# SF32LB57x register map
File version: 1.0
CPU: CM33 r0p1, little endian, MPU, FPU, 3 interrupt priority bits
Registers are 32-bit, read-write, reset 0x0 unless marked. A register's access mark holds for its fields unless they carry their own. Offsets are from the block's base; [hi:lo] are bit positions; {n}, {i} and the like mark numbered series; 'fields as' and 'values as' point back to an identical list.

## EPIC
Base 0x50007000
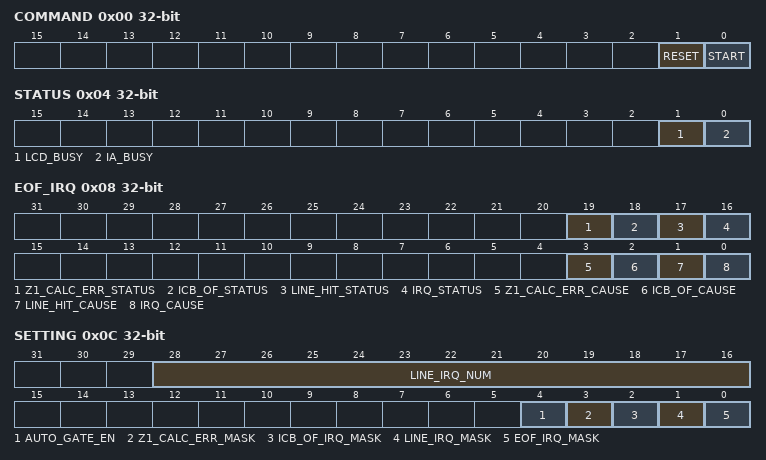
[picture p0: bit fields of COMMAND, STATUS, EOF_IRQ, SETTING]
0x00 COMMAND
  [1] RESET — 1: reset the whole graphics 0: release the reset
  [0] START — write 1 to trigger the lcd interface block
0x04 STATUS
  [1] LCD_BUSY — LCD controll busy flag
  [0] IA_BUSY — Graphics accelerator busy flag
0x08 EOF_IRQ
  [19] Z1_CALC_ERR_STATUS — raw status of z1 calculation error interrupt
  [18] ICB_OF_STATUS — raw status of decomp icb overflow interrupt
  [17] LINE_HIT_STATUS — raw status of line hit interrupt
  [16] IRQ_STATUS — raw status of end of frame interrupt
  [3] Z1_CALC_ERR_CAUSE — z1 calculation error interrupt, can be masked by Z1_CALC_ERR_MASK
  [2] ICB_OF_CAUSE — decomp icb overflow interrupt, can be masked by ICB_OF_IRQ_MASK
  [1] LINE_HIT_CAUSE — line hit interrupt, can be masked by LINE_IRQ_MASK
  [0] IRQ_CAUSE — end of frame interrupt, can be masked by EOF_IRQ_MASK
0x0C SETTING
  [28:16] LINE_IRQ_NUM — canvas line hit interrupt line number
  [4] AUTO_GATE_EN — auto clock gating enable
  [3] Z1_CALC_ERR_MASK — z1 calculation error interrupt mask, 0: mask the interrupt
  [2] ICB_OF_IRQ_MASK — icb overflow interrupt mask, 0: mask the interrupt
  [1] LINE_IRQ_MASK — canvas line hit interrupt mask, 0: mask the interrupt
  [0] EOF_IRQ_MASK — end of frame interrupt mask, 0: mask the interrupt
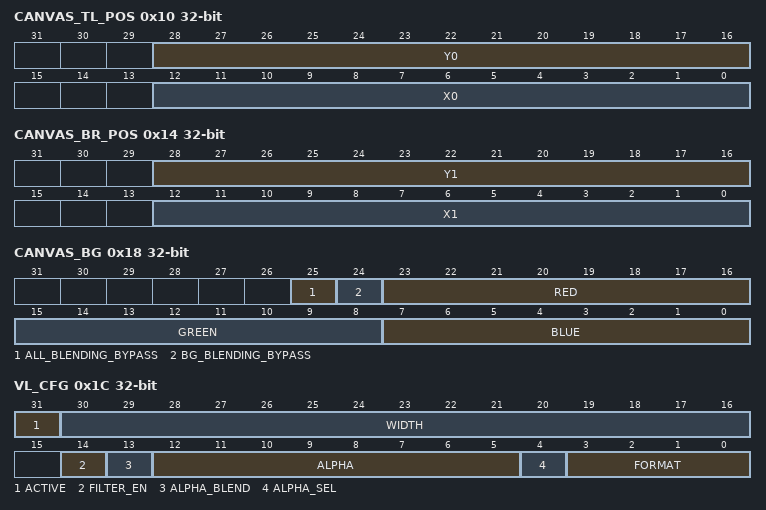
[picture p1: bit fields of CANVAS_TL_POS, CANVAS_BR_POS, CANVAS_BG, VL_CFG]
0x10 CANVAS_TL_POS — Top-Left pixel coordinate
  [28:16] Y0, [12:0] X0
0x14 CANVAS_BR_POS — Bottom-Right pixel coordinate
  [28:16] Y1, [12:0] X1
0x18 CANVAS_BG — Background color
  [25] ALL_BLENDING_BYPASS — if this bit is set, epic is in pure dma mode. No blending operation.
  [24] BG_BLENDING_BYPASS — if this bit is set, the layer is not blending with background. The alpha value will be reserved to output.
  [23:16] RED — Red color
  [15:8] GREEN — green color
  [7:0] BLUE — blue color
0x1C VL_CFG
  [31] ACTIVE — layer active flag
  [30:16] WIDTH — source image width(including padding), unit is bytes
  [14] FILTER_EN — layer color filter enable
  [13] ALPHA_BLEND — set 1 to enable alpha blending mode. Use layer alpha as blending factor for image with Alpha. Alpha_out = Layer_alpha * Image_alpha
  [12:5] ALPHA — layer alpha value
  [4] ALPHA_SEL — alpha selection 1'b0: select alpha according to image format 1'b1: select layer alpha
  [3:0] FORMAT — video layer input format 4'h0: RGB565 4'h1: RGB888 4'h2: ARGB8888 4'h3: ARGB8565 4'h4: A8 4'h5: A4 4'h6: L8 4'h7: A2 4'h8: L4 other: reserved
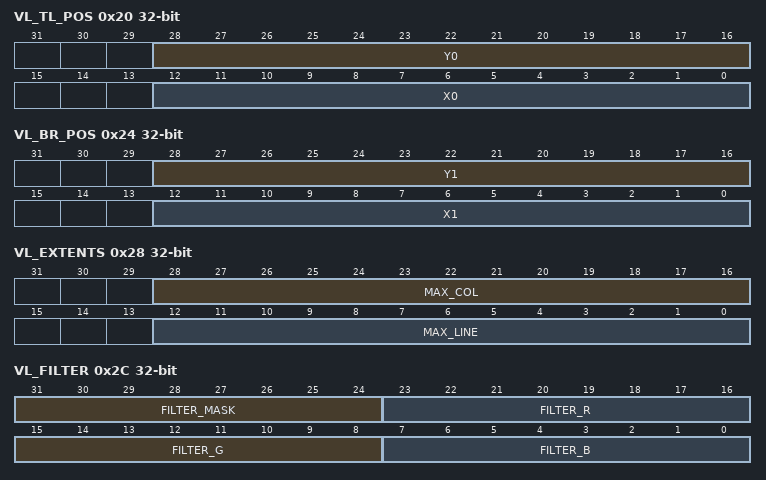
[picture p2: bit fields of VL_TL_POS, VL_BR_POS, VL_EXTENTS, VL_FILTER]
0x20 VL_TL_POS
  [28:16] Y0 — Coordingate Y-value
  [12:0] X0 — Coordinate X-value
0x24 VL_BR_POS
  [28:16] Y1 — Coordingate Y-value
  [12:0] X1 — Coordinate X-value
0x28 VL_EXTENTS
  [28:16] MAX_COL — max column number of source image(not including padding)
  [12:0] MAX_LINE — max line number of source image(not including padding)
0x2C VL_FILTER
  [31:24] FILTER_MASK — layer color filter mask
  [23:16] FILTER_R — filter r color
  [15:8] FILTER_G — filter g color
  [7:0] FILTER_B — filter b color
0x30 VL_SRC
  [31:0] ADDR — source image RGB data address[31:0]. For RGB565 format, address should be aligned to halfword. For ARGB8888 format, address should be aligned to word.
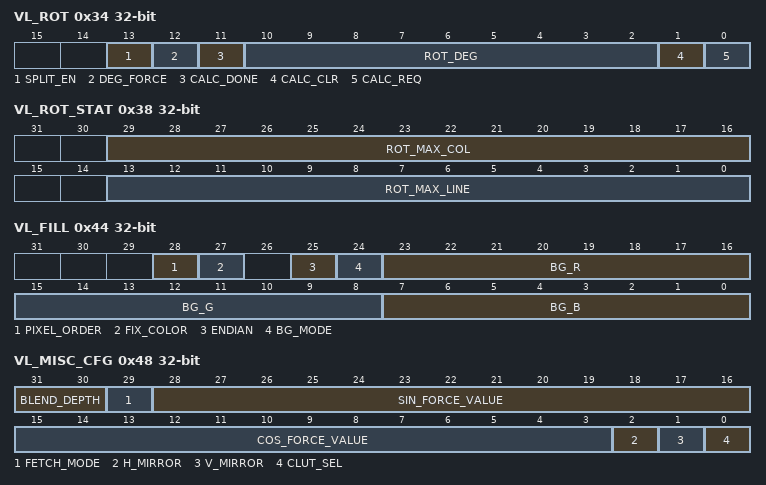
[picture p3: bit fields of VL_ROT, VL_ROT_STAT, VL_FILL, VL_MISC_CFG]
0x34 VL_ROT
  [13] SPLIT_EN — split read access of rotation
  [12] DEG_FORCE — force epic use external sin and cos value, quadrant is still calculated from ROT_DEG.
  [11] CALC_DONE — calculation done indicator
  [10:2] ROT_DEG — rotation degree, rotation is clockwise.
  [1] CALC_CLR — rot_max_col and rot_max_line calculation clear request. Write 1 to clear the result.
  [0] CALC_REQ — rot_max_col and rot_max_line calculation request. Write 1 to trigger the calculation.
0x38 VL_ROT_STAT
  [29:16] ROT_MAX_COL — max column of rotated image
  [13:0] ROT_MAX_LINE — max line of rotated image
0x3C VL_SCALE_RATIO_H
  [28:0] XPITCH — x-axis rescaling ration, 13.16 fixed point number, XPITCH lt MAX_COL/(X1-X0)
0x40 VL_SCALE_RATIO_V
  [28:0] YPITCH — y-axis rescaling ratio, 13.16 fixed point number, YPITCH lt MAX_LINE/(Y1-Y0)
0x44 VL_FILL
  [28] PIXEL_ORDER — A4, A2, L4 color format pixel order 0: ByteA4 = {P1, P0}, ByteA2 = (P3, P2, P1, P0), ByteL4 = {P1, P0} 1: ByteA4 = {P0, P1}, ByteA2 = (P0, P1, P2, P3), ByteL4 = {P0, P1}
  [27] FIX_COLOR — set this bit to 1, this layer output will be fixed to Alpha, BG_R, BG_G and BG_B
  [25] ENDIAN — input 565 data format endian 0: {R[4:0], G[5:3], G[2:0], B[4:0]} 1: {G[2:0], B[4:0], R[4:0], G[5:3]}
  [24] BG_MODE — Not used.
  [23:16] BG_R — background r color
  [15:8] BG_G — background g color
  [7:0] BG_B — background b color
0x48 VL_MISC_CFG
  [31:30] BLEND_DEPTH — video layer blending depth
  [29] FETCH_MODE — 1: use undefined length AHB transaction 0: use fixed length AHB transaction
  [28:16] SIN_FORCE_VALUE — external absolute value of sin. U1.12 format.
  [15:3] COS_FORCE_VALUE — external absolute value of cos. U1.12 format.
  [2] H_MIRROR — horizontal mirror enable
  [1] V_MIRROR — vertical mirror enable
  [0] CLUT_SEL — VL CLUT select: 1'h1: select pallette1 1'h0: select pallette0
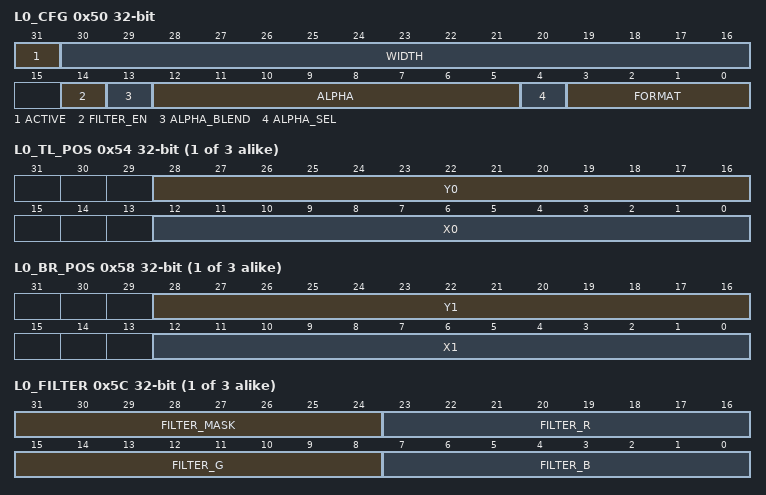
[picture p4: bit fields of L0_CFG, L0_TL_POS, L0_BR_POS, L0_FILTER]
0x50 L0_CFG
  [31] ACTIVE — layer active flag
  [30:16] WIDTH — source image width(including padding), unit is bytes
  [14] FILTER_EN — layer color filter enable
  [13] ALPHA_BLEND — set 1 to enable alpha blending mode. Use layer alpha as blending factor for image with Alpha. Alpha_out = Layer_alpha * Image_alpha
  [12:5] ALPHA — layer alpha value
  [4] ALPHA_SEL — alpha selection 1'b0: select alpha according to image format 1'b1: select layer alpha
  [3:0] FORMAT — layer input format 4'h0: RGB565 4'h1: RGB888 4'h2: ARGB8888 4'h3: ARGB8565 4'h4: A8 4'h5: A4 4'h6: L8 4'h7: A2 4'h8: L4 other: reserved
{0x54+0x20*i} L{i}_TL_POS (i=0..2)
  [28:16] Y0 — Coordingate Y-value
  [12:0] X0 — Coordinate X-value
{0x58+0x20*i} L{i}_BR_POS (i=0..2)
  [28:16] Y1 — Coordingate Y-value
  [12:0] X1 — Coordinate X-value
{0x5C+0x20*i} L{i}_FILTER (i=0..2)
  fields as VL_FILTER
{0x60+0x20*i} L{i}_SRC (i=0..2)
  fields as VL_SRC
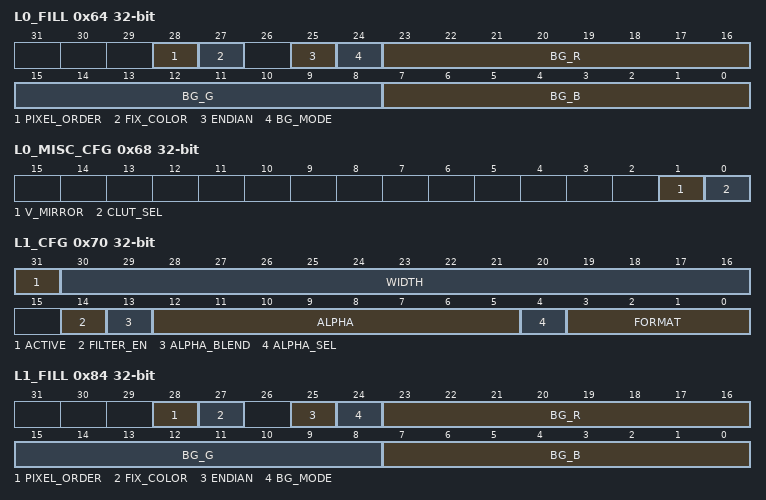
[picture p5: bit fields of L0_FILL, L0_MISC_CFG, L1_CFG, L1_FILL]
0x64 L0_FILL
  fields as VL_FILL
0x68 L0_MISC_CFG
  [1] V_MIRROR — vertical mirror enable
  [0] CLUT_SEL — L0 CLUT select: 1'h1: select pallette1 1'h0: select pallette0
0x70 L1_CFG
  fields as L0_CFG
0x84 L1_FILL
  [28] PIXEL_ORDER — A4, A2, L4 color format pixel order 0: ByteA4 = {P1, P0}, ByteA2 = (P3, P2, P1, P0), ByteL4 = {P1, P0} 1: ByteA4 = {P0, P1}, ByteA2 = (P0, P1, P2, P3), ByteL4 = {P0, P1}
  [27] FIX_COLOR — set this bit to 1, this layer output will be fixed to Alpha, BG_R, BG_G and BG_B
  [25] ENDIAN — input 565 data format endian 0: {R[4:0], G[5:3], G[2:0], B[4:0]} 1: {G[2:0], R[4:0], B[4:0], G[5:3]}
  [24] BG_MODE — Not used.
  [23:16] BG_R — background r color
  [15:8] BG_G — background g color
  [7:0] BG_B — background b color
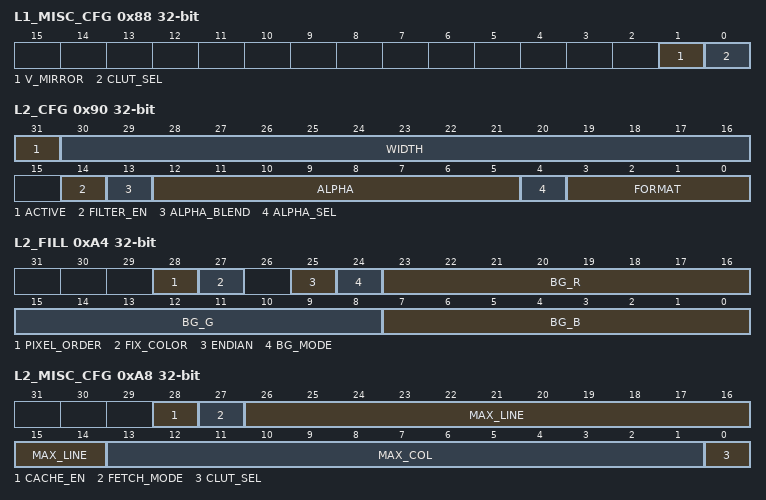
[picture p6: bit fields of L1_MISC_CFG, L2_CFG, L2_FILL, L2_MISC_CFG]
0x88 L1_MISC_CFG
  [1] V_MIRROR — vertical mirror enable
  [0] CLUT_SEL — L1 CLUT select: 1'h1: select pallette1 1'h0: select pallette0
0x90 L2_CFG
  [31] ACTIVE — layer active flag
  [30:16] WIDTH — source image width(including padding), unit is bytes
  [14] FILTER_EN — layer color filter enable
  [13] ALPHA_BLEND — set 1 to enable alpha blending mode. Use layer alpha as blending factor for image with Alpha. Alpha_out = Layer_alpha * Image_alpha
  [12:5] ALPHA — layer alpha value
  [4] ALPHA_SEL — alpha selection 1'b0: select alpha according to image format 1'b1: select layer alpha
  [3:0] FORMAT — layer input format 4'h0: RGB565 4'h1: RGB888 4'h2: ARGB8888 4'h3: ARGB8565 Other: reserved
0xA4 L2_FILL
  [28] PIXEL_ORDER — Not used.
  [27] FIX_COLOR — set this bit to 1, this layer output will be fixed to Alpha, BG_R, BG_G and BG_B
  [25] ENDIAN — input 565 data format endian 0: {R[4:0], G[5:3], G[2:0], B[4:0]} 1: {G[2:0], B[4:0], R[4:0], G[5:3]}
  [24] BG_MODE — Not used.
  [23:16] BG_R — background r color
  [15:8] BG_G — background g color
  [7:0] BG_B — background b color
0xA8 L2_MISC_CFG
  [28] CACHE_EN — 1: enable L2 data fetch cache
  [27] FETCH_MODE — 1: use undefined length AHB transaction 0: use fixed length AHB transaction
  [26:14] MAX_LINE — max line of image
  [13:1] MAX_COL — max column of image
  [0] CLUT_SEL — L1 CLUT select: 1'h1: select pallette1 1'h0: select pallette0
0xAC L2_MAT_A0
  [31:0] VAL — s12.20
0xB0 L2_MAT_A1
  [31:0] VAL — s12.20
0xB4 L2_MAT_A2
  [31:0] VAL — s16.16
0xB8 L2_MAT_B0
  [31:0] VAL — s12.20
0xBC L2_MAT_B1
  [31:0] VAL — s12.20
0xC0 L2_MAT_B2
  [31:0] VAL — s16.16
0xC4 L2_MAT_C0
  [31:0] VAL — s12.20
0xC8 L2_MAT_C1
  [31:0] VAL — s12.20
0xCC L2_MAT_C2
  [31:0] VAL — s16.16
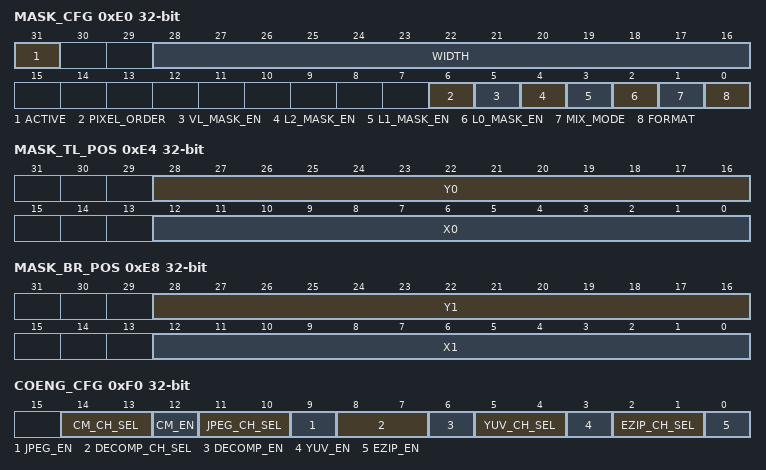
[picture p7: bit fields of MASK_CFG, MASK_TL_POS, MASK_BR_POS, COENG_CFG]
0xE0 MASK_CFG
  [31] ACTIVE — layer active flag
  [28:16] WIDTH — source image width(including padding), unit is bytes
  [6] PIXEL_ORDER — A4 color format pixel order 0: ByteA4 = {P1, P0} 1: ByteA4 = {P0, P1}
  [5] VL_MASK_EN — video layer mask enable
  [4] L2_MASK_EN — layer2 mask enable
  [3] L1_MASK_EN — layer1 mask enable
  [2] L0_MASK_EN — layer0 mask enable
  [1] MIX_MODE — mask mix mode 1'h0: mult mode 1'h1: overwrite mode
  [0] FORMAT — mask input format 1'h0: A8 1'h1: A4
0xE4 MASK_TL_POS
  [28:16] Y0 — Coordingate Y-value
  [12:0] X0 — Coordinate X-value
0xE8 MASK_BR_POS
  [28:16] Y1 — Coordingate Y-value
  [12:0] X1 — Coordinate X-value
0xEC MASK_SRC
  [31:0] ADDR — mask data address[31:0]. This is byte address, even for A4, this address is byte aligned.
0xF0 COENG_CFG
  [14:13] CM_CH_SEL — color matrix engine channel select 2'h0: VL 2'h1: OL0 2'h2: OL1 2'h3: OL2
  [12] CM_EN — color matrix enable
  [11:10] JPEG_CH_SEL — jpeg engine channel select 2'h0: VL 2'h1: OL0 2'h2: OL1 2'h3: reserved
  [9] JPEG_EN — jpeg enable
  [8:7] DECOMP_CH_SEL — decompression channel select 2'h0: VL 2'h1: OL0 2'h2: OL1 2'h3: reserved
  [6] DECOMP_EN — decompression enable
  [5:4] YUV_CH_SEL — yuv engine channel select 2'h0: VL 2'h1: OL0 2'h2: OL1 2'h3: reserved
  [3] YUV_EN — yuv enable
  [2:1] EZIP_CH_SEL — ezip channel select 2'h0: VL 2'h1: OL0 2'h2: OL1 2'h3: reserved
  [0] EZIP_EN — ezip enable
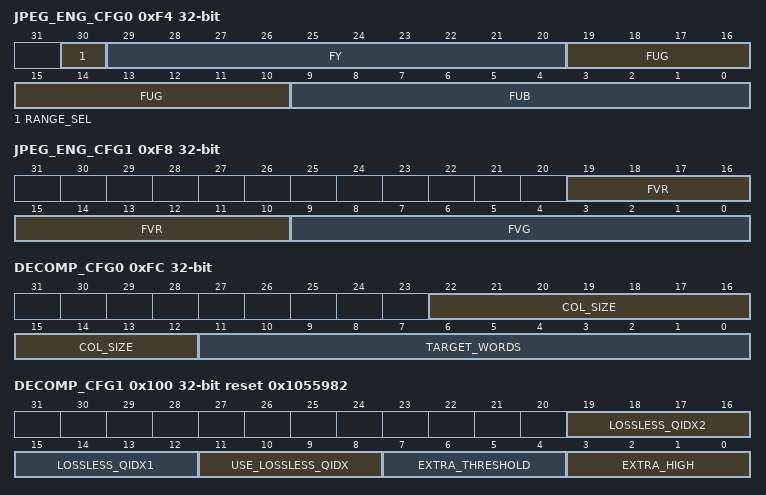
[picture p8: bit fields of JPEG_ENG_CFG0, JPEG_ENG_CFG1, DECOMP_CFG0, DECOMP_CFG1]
0xF4 JPEG_ENG_CFG0
  [30] RANGE_SEL — yuv input range 1'h0: tv range 1'h1: pc range
  [29:20] FY — YUV Fy coef
  [19:10] FUG — YUV Fug coef
  [9:0] FUB — YUV Fub coef
0xF8 JPEG_ENG_CFG1
  [19:10] FVR — YUV Fvr coef
  [9:0] FVG — YUV Fvg coef
0xFC DECOMP_CFG0
  [22:12] COL_SIZE — number of colums in a line of original image, max column size is 1024
  [11:0] TARGET_WORDS — size of a single channel data before decompression. Unit is half word. Each line has 3 channels. So for each line, the compressed data size is target_words * 3 * 2 bytes.
0x100 DECOMP_CFG1 reset 0x1055982
  [19:16] LOSSLESS_QIDX2 — condition to decrease qidx
  [15:12] LOSSLESS_QIDX1 — up level for adjusted qidx value for low quality block
  [11:8] USE_LOSSLESS_QIDX — condition to increase qidx
  [7:4] EXTRA_THRESHOLD — the threshold to distinguish high/low quality block
  [3:0] EXTRA_HIGH — extra bit for high quality bit
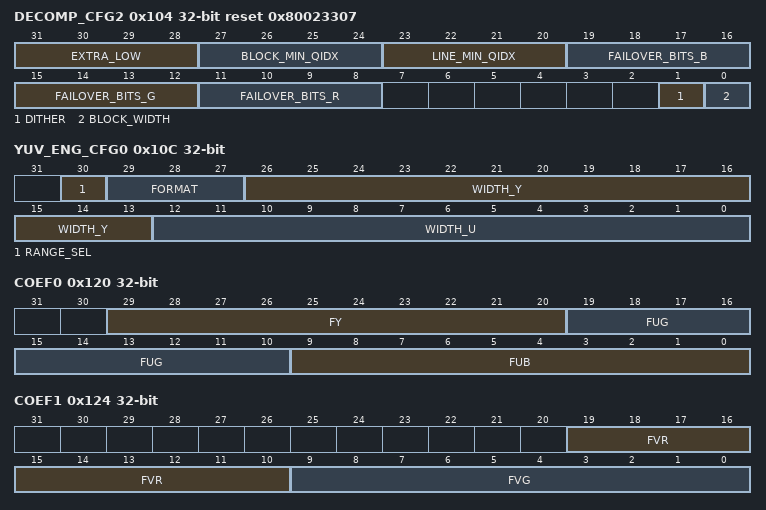
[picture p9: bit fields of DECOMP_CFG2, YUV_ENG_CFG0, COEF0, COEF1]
0x104 DECOMP_CFG2 reset 0x80023307
  [31:28] EXTRA_LOW — extra bit for low quality block
  [27:24] BLOCK_MIN_QIDX — minimum qidx for block mode
  [23:20] LINE_MIN_QIDX — minimum qidx for line mode
  [19:16] FAILOVER_BITS_B — failover compression mode target bits(Blue)
  [15:12] FAILOVER_BITS_G — failover compression mode target bits(Green)
  [11:8] FAILOVER_BITS_R — failover compression mode target bits(Red)
  [1] DITHER — dithering function 0: off 1: on
  [0] BLOCK_WIDTH — block_size in pixel unit. 0: 16 pixels 1: 32 pixels Small block size will cause more blocks and more bits to store block information.
0x108 DECOMP_STAT
  [6:0] BUF_MAX_DEPTH — buf max usage
0x10C YUV_ENG_CFG0
  [30] RANGE_SEL — yuv input range 1'h0: tv range 1'h1: pc range
  [29:27] FORMAT — yuv format
  [26:13] WIDTH_Y — yuv y vector line width, unit is bytes
  [12:0] WIDTH_U — yuv u vector line width, unit is bytes
0x110 YUV_ENG_CFG1
  [12:0] WIDTH_V — yuv v vector line width, unit is bytes
0x114 Y_SRC
  [31:0] ADDR — y vector address
0x118 U_SRC
  [31:0] ADDR — u vector address
0x11C V_SRC
  [31:0] ADDR — v vector address
0x120 COEF0
  [29:20] FY — YUV Fy coef
  [19:10] FUG — YUV Fug coef
  [9:0] FUB — YUV Fub coef
0x124 COEF1
  [19:10] FVR — YUV Fvr coef
  [9:0] FVG — YUV Fvg coef
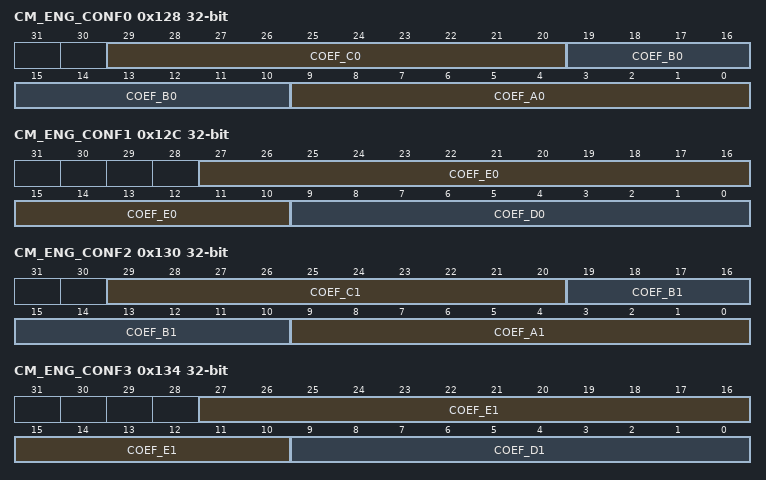
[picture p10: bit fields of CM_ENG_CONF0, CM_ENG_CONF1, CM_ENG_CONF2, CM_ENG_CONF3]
0x128 CM_ENG_CONF0
  [29:20] COEF_C0 — c0, s2.8 format
  [19:10] COEF_B0 — b0, s2.8 format
  [9:0] COEF_A0 — a0, s2.8 format
0x12C CM_ENG_CONF1
  [27:10] COEF_E0 — e0, s10.8 format
  [9:0] COEF_D0 — d0, s2.8 format
0x130 CM_ENG_CONF2
  [29:20] COEF_C1 — c1, s2.8 format
  [19:10] COEF_B1 — b1, s2.8 format
  [9:0] COEF_A1 — a1, s2.8 format
0x134 CM_ENG_CONF3
  [27:10] COEF_E1 — e1, s10.8 format
  [9:0] COEF_D1 — d1, s2.8 format
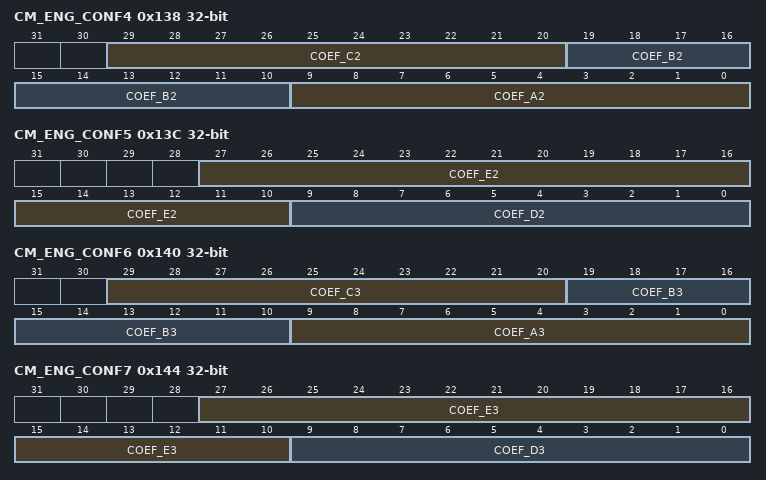
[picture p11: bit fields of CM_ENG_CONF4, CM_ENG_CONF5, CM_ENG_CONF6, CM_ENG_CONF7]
0x138 CM_ENG_CONF4
  [29:20] COEF_C2 — c2, s2.8 format
  [19:10] COEF_B2 — b2, s2.8 format
  [9:0] COEF_A2 — a2, s2.8 format
0x13C CM_ENG_CONF5
  [27:10] COEF_E2 — e2, s10.8 format
  [9:0] COEF_D2 — d2, s2.8 format
0x140 CM_ENG_CONF6
  [29:20] COEF_C3 — c3, s2.8 format
  [19:10] COEF_B3 — b3, s2.8 format
  [9:0] COEF_A3 — a3, s2.8 format
0x144 CM_ENG_CONF7
  [27:10] COEF_E3 — e3, s10.8 format
  [9:0] COEF_D3 — d3, s2.8 format
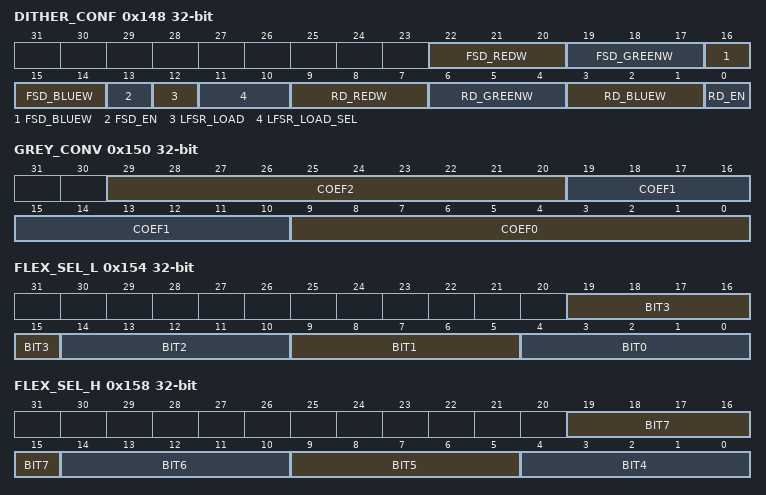
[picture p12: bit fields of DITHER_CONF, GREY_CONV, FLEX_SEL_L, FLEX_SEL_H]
0x148 DITHER_CONF
  [22:20] FSD_REDW — red regular dither width, range from 0 - 4
  [19:17] FSD_GREENW — green regular dither width, range from 0 - 4
  [16:14] FSD_BLUEW — blue regular dither width, range from 0 - 4
  [13] FSD_EN — regular dither enable
  [12] LFSR_LOAD — load random dither lfsr init value
  [11:10] LFSR_LOAD_SEL — select random dither lfsr 0: none 1: red 2: green 3: blue
  [9:7] RD_REDW — red random dither width
  [6:4] RD_GREENW — green random dither width
  [3:1] RD_BLUEW — blue random dither width
  [0] RD_EN — random dither enable
0x14C DITHER_LFSR
  [31:0] INIT_VAL — random dither lfsr init load value
0x150 GREY_CONV
  [29:20] COEF2
  [19:10] COEF1
  [9:0] COEF0 — grey = (coef0 * r + coef1 * g + coef2 * b) >> 10
0x154 FLEX_SEL_L
  [19:15] BIT3
  [14:10] BIT2
  [9:5] BIT1
  [4:0] BIT0 — bit select index from internal ARGB8888 format data
0x158 FLEX_SEL_H
  [19:15] BIT7
  [14:10] BIT6
  [9:5] BIT5
  [4:0] BIT4 — bit select index from internal ARGB8888 format data
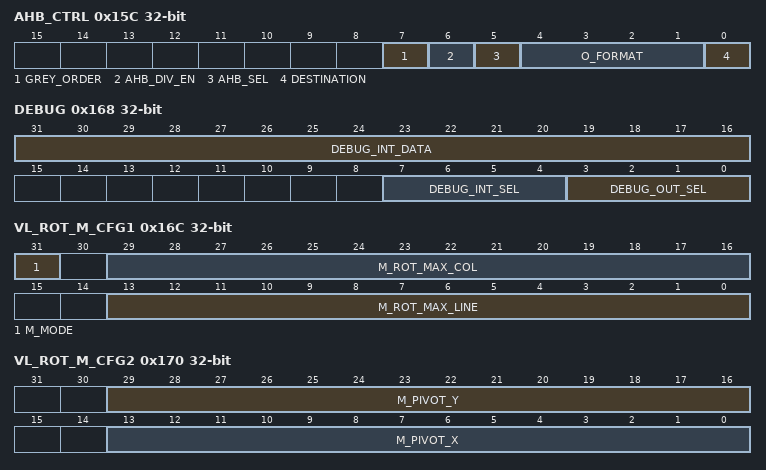
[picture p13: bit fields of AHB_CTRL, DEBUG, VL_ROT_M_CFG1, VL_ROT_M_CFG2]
0x15C AHB_CTRL
  [7] GREY_ORDER — G4/G2 format bit order 1'h0: byteG4 = {p1, p0}, byteG2 = {p3,p2,p1,p0} 1'h1: byteG4 = {p0, p1}, byteG2 = {p0,p1,p2,p3}
  [6] AHB_DIV_EN — set 1 to divide AHB undefined length burst to fix length burst
  [5] AHB_SEL — select ahb write interface: 1'b0: select AHB_A 1'b1: select AHB_B
  [4:1] O_FORMAT — AHB output format: 4'h0: RGB565 4'h1: RGB888 4'h2: ARGB8888 4'h3: ARGB8565 4'h4: A8 4'h5: G8(8 bit for 1 pixel) 4'h6: G4(4 bit for 1 pixel) 4'h7: G2(2bit for 1 pixel) 4'h8: F8(Flexible 8bit format) 4'h9: F4(Flexible 4bit format) 4'ha: F2(Flexible 2bit format) other: reserved
  [0] DESTINATION — The Data can be sent to two destinations: 2'b0: AHB RAM 2'b1: AHB LCD
0x160 AHB_MEM
  [31:0] ADDR — AHB RAM/AHB LCD target address
0x164 AHB_STRIDE
  [15:0] OFFSET
0x168 DEBUG
  [31:16] DEBUG_INT_DATA, [7:4] DEBUG_INT_SEL, [3:0] DEBUG_OUT_SEL
0x16C VL_ROT_M_CFG1
  [31] M_MODE — rotation mode setting 1'b0: auto mode 1'b1: manual mode
  [29:16] M_ROT_MAX_COL — manual mode rotation max column, unsigned value
  [13:0] M_ROT_MAX_LINE — manual mode rotation max line, unsigned value
0x170 VL_ROT_M_CFG2
  [29:16] M_PIVOT_Y — manual mode pivot y, signed value, -8191~8191, -8192 is not supported
  [13:0] M_PIVOT_X — manual mode pivot x, signed value, -8191~8191, -8192 is not supported
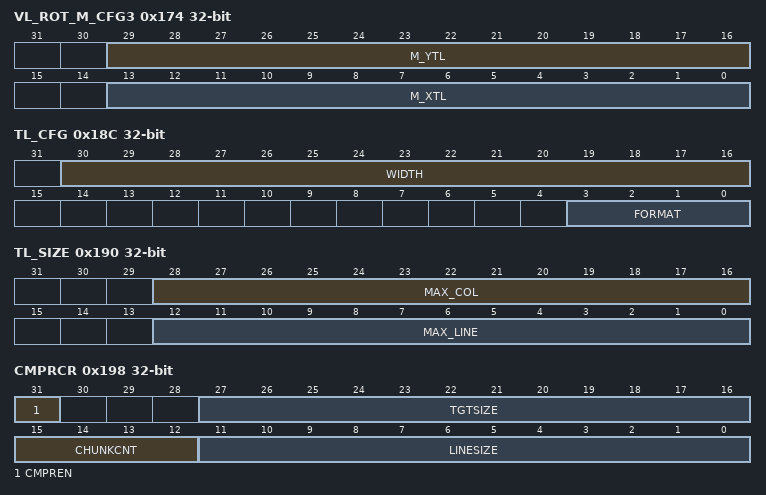
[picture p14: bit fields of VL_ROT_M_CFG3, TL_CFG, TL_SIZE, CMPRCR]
0x174 VL_ROT_M_CFG3
  [29:16] M_YTL — manual mode top left y cordinate, signed value, -8191~8191, -8192 is not supported
  [13:0] M_XTL — manual mode top left x cordinate, signed value, -8191~8191, -8192 is not supported
0x178 VL_SCALE_INIT_CFG1
  [28:0] X_VAL — x-axis scale initial value, 13.16 format
0x17C VL_SCALE_INIT_CFG2
  [28:0] Y_VAL — y-axis scale initial value, 13.16 format
0x180 AHBA_CNT
  [31:0] VAL — epic ahb_a bus busy cycle counter
0x184 AHBB_CNT
  [31:0] VAL — epic ahb_b bus busy cycle counter
0x188 PERF_CNT
  [31:0] VAL — epic performance counter
0x18C TL_CFG
  [30:16] WIDTH — source image width(including padding), unit is bytes
  [3:0] FORMAT — Transfer layer input format 4'h0: RGB565 4'h1: RGB888 4'h2: ARGB8888 4'h3: ARGB8565 4'h4: A8 other: reserved
0x190 TL_SIZE
  [28:16] MAX_COL — max line number
  [12:0] MAX_LINE — max column number
0x194 TL_SRC
  fields as VL_SRC
0x198 CMPRCR — Image Compression control register
  [31] CMPREN — Compression enable
  [27:16] TGTSIZE — output target size of each chunk after compression. output data size of each image line is tgtsize*chunkcnt*3*2 bytes
  [15:12] CHUNKCNT — number of chunks for each image line
  [11:0] LINESIZE — number of pixels of each Chunk. Input data size of each image line is linesize*chunkcnt*(size per pixel)
0x19C CMPRCFG0 reset 0x80023307 — Compression configuration 0
  [31:0] CFG — Compression configuration
0x1A0 CMPRCFG1 reset 0x1055982 — Compression configuration 1
  [31:0] CFG — Compression configuration
0x1A4 CMPRQR — Compression quality register
  [28:16] DUMMY — line least dummy word in one frame, update every frame.
  [15:8] LQB — low quality block number. the bigger of this number, the worse compressed image quality
  [7:0] LQR — quality sum to low qulity block number ratio. the bigger of this number, the worse compressed image quality.
0x1A8 CMPRDR — Compression debug register
  [6:0] MAXBUF — record of max used buffer during compression output
0x1AC TL_GREY_CONV
  fields as GREY_CONV
0x1B0 TL_FLEX_SEL_L
  fields as FLEX_SEL_L
0x1B4 TL_FLEX_SEL_H
  fields as FLEX_SEL_H
0x1B8 TL_AHB_CTRL
  [5] GREY_ORDER — G4 format bit order 1'h0: byteG4 = {p1, p0}, byteG2 = {p3,p2,p1,p0} 1'h1: byteG4 = {p0, p1}, byteG2 = {p0,p1,p2,p3}
  [4] AHB_DIV_EN — set 1 to divide AHB undefined length burst to fix length burst
  [3:0] O_FORMAT — AHB output format: 4'h0: RGB565 4'h1: RGB888 4'h2: ARGB8888 4'h3: ARGB8565 4'h4: A8 4'h5: G8(8 bit for 1 pixel) 4'h6: G4(4 bit for 1 pixel) 4'h7: G2(2bit for 1 pixel) 4'h8: F8(Flexible 8bit format) 4'h9: F4(Flexible 4bit format) 4'ha: F2(Flexible 2bit format) other: reserved
0x1BC TL_AHB_MEM
  [31:0] ADDR — transfer layer AHB RAM target address
0x1C0 TL_AHB_STRIDE
  [15:0] OFFSET
0x1C4 TL_COMMAND
  [1] RESET — 1: reset the TL block 0: release the reset
  [0] START — write 1 to trigger the transfer layer
0x1C8 TL_STATUS
  [1] TL_CTRL_BUSY — transfer controller busy
  [0] TL_BUSY — transfer engine busy flag
0x1CC TL_IRQ
  [18] OCB_OF_STATUS — raw status of ocb overflow interrupt
  [17] LINE_HIT_STATUS — transfer layer line hit interrupt
  [16] EOT_STATUS — end of transfer interrupt
  [2] OCB_OF_CAUSE — ocb overflow interrupt, can be masked by OCB_OF_IRQ_MASK
  [1] LINE_HIT_CAUSE — transfer layer line hit interrupt, can be masked by LINE_IRQ_MASK
  [0] EOT_CAUSE — end of transfer interrupt, can be masked by EOT_IRQ_MASK
0x1D0 TL_SETTING
  [28:16] LINE_IRQ_NUM — canvas line hit interrupt line number
  [2] OCB_OF_IRQ_MASK — comp ocb overflow interrupt mask, 0: mask the interrupt
  [1] LINE_IRQ_MASK — transfer layer line hit interrupt mask, 0: mask the interrupt
  [0] EOT_IRQ_MASK — end of transfer interrupt mask, 0: mask the interrupt
0x1D4 TL_PERF_CNT
  [31:0] VAL — transfer layer performance counter
0x1D8 CANVAS_STAT0
  [11:9] FETCH_STAT — fetch status
  [8:6] PREC_STAT — prec status
  [5:3] POSTC_STAT — postc_status
  [2:0] FIFO_CNT — pre calc fifo count
0x1DC CANVAS_STAT1
  [28:16] Y_COR — current epic engine y cordinate. start from canvas_tl_y + 1 to canvas_br_y + 1. Check this to figure where the epic engine is stucked.
  [12:0] X_COR — current epic engine x cordinate. start from canvas_tl_x to canvas_br_x. Check this to figure where the epic engine is stucked.
0x1E0 ENG_STAT
  [31:29] JPEG_RUN_STAT — jpeg engine status
  [28:16] JPEG_LINE_CNT — jpeg engine line count
  [15:13] EZIP_RUN_STAT — ezip engine status
  [12:0] EZIP_LINE_CNT — ezip engine line count
0x1E4 OL_STAT
  [23:21] PF_PR1, [20:19] PF_DF1, [18:17] DATA_CONV1, [16] DONE_REQ1, [7:5] PF_PR0, [4:3] PF_DF0, [2:1] DATA_CONV0, [0] DONE_REQ0
0x1E8 OL2_STAT
  [7:5] PF_PR2, [4:3] PF_DF2, [2:1] DATA_CONV2, [0] DONE_REQ2
0x1EC VL_STAT
  [26:25] SC_LB0, [24:23] SC_LB1, [22:19] SC_FE, [18:16] SC_BE, [15:14] SC_OUT, [13:12] NF_DATA_CONV, [11:10] NF_DF, [9:7] NF_PR, [6:3] RF_ROT_BE, [2:0] RF_ROT_FE
0x1F0 ML_STAT
  [5:3] MF_PR, [2:1] MF_DF, [0] DONE_REQ
0x1F4 TL_STAT0
  [28:16] Y_COR — canvas y cordinate
  [12:0] X_COR — canvas x cordinate
0x1F8 TL_STAT1
  [27:20] AHB_CTRL_FIFO_CNT, [19] AHB_CTRL_EOL, [18:16] AHB_CTRL, [7:5] PF_PR, [4:3] PF_DF, [2:1] DATA_CONV, [0] DONE_REQ
0x1FC MEM_IF_STAT
  [31:24] AHB_CTRL_FIFO_CNT, [23] AHB_CTRL_EOL, [22:20] AHB_CTRL, [19:17] ARB_MAIN1, [16:14] ARB_READ_PORT1, [13:10] AHB1, [9:7] ARB_MAIN0, [6:4] ARB_READ_PORT0, [3:0] AHB0
